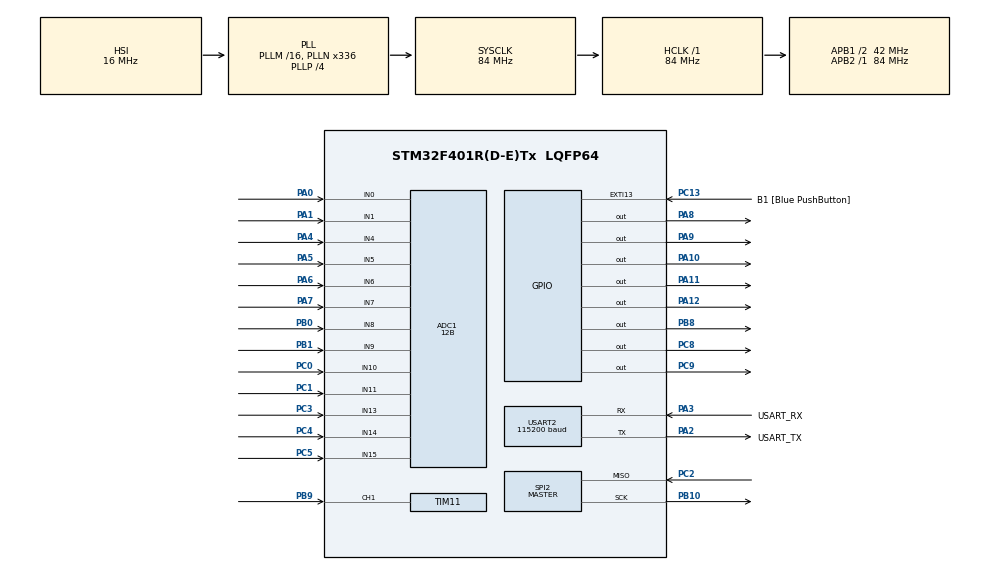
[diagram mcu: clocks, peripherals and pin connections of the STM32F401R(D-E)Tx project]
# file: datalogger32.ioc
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ADC1.Channel-0\#ChannelRegularConversion=ADC_CHANNEL_0
ADC1.ClockPrescaler=ADC_CLOCK_SYNC_PCLK_DIV4
ADC1.ContinuousConvMode=DISABLE
ADC1.DMAContinuousRequests=DISABLE
ADC1.DataAlign=ADC_DATAALIGN_RIGHT
ADC1.DiscontinuousConvMode=DISABLE
ADC1.EOCSelection=ADC_EOC_SINGLE_CONV
ADC1.EnableAnalogWatchDog=false
ADC1.ExternalTrigConv=ADC_SOFTWARE_START
ADC1.ExternalTrigConvEdge=ADC_EXTERNALTRIGCONVEDGE_NONE
ADC1.InjNumberOfConversion=0
ADC1.NbrOfConversion=1
ADC1.NbrOfConversionFlag=1
ADC1.Rank-0\#ChannelRegularConversion=1
ADC1.Resolution=ADC_RESOLUTION_12B
ADC1.SamplingTime-0\#ChannelRegularConversion=ADC_SAMPLETIME_3CYCLES
ADC1.ScanConvMode=DISABLE
ADC1.master=1
Dma.Request0=USART2_RX
Dma.USART2_RX.0.Direction=DMA_PERIPH_TO_MEMORY
Dma.USART2_RX.0.FIFOMode=DMA_FIFOMODE_DISABLE
Dma.USART2_RX.0.Instance=DMA1_Stream5
Dma.USART2_RX.0.MemDataAlignment=DMA_MDATAALIGN_BYTE
Dma.USART2_RX.0.MemInc=DMA_MINC_ENABLE
Dma.USART2_RX.0.Mode=DMA_CIRCULAR
Dma.USART2_RX.0.PeriphDataAlignment=DMA_PDATAALIGN_BYTE
Dma.USART2_RX.0.PeriphInc=DMA_PINC_DISABLE
Dma.USART2_RX.0.Priority=DMA_PRIORITY_LOW
Mcu.Family=STM32F4
Mcu.Name=STM32F401R(D-E)Tx
Mcu.Package=LQFP64
NVIC.DMA1_Stream5_IRQn=true\:0\:0\:false\:false\:true\:false
NVIC.PriorityGroup=NVIC_PRIORITYGROUP_0
NVIC.TIM1_TRG_COM_TIM11_IRQn=true\:0\:0\:false\:false\:true\:true
PA0-WKUP.Signal=ADCx_IN0
PA1.Signal=ADCx_IN1
PA10.GPIO_PuPd=GPIO_PULLDOWN
PA10.Signal=GPIO_Output
PA11.GPIO_PuPd=GPIO_PULLDOWN
PA11.Signal=GPIO_Output
PA12.GPIO_ModeDefaultOutputPP=GPIO_MODE_OUTPUT_PP
PA12.GPIO_PuPd=GPIO_PULLDOWN
PA12.Signal=GPIO_Output
PA13.GPIO_Label=TMS
PA13.Mode=Serial_Wire
PA13.Signal=SYS_JTMS-SWDIO
PA14.GPIO_Label=TCK
PA14.Mode=Serial_Wire
PA14.Signal=SYS_JTCK-SWCLK
PA2.GPIO_Label=USART_TX
PA2.GPIO_Mode=GPIO_MODE_AF_PP
PA2.GPIO_PuPd=GPIO_PULLUP
PA2.GPIO_Speed=GPIO_SPEED_FREQ_HIGH
PA2.Mode=Asynchronous
PA2.Signal=USART2_TX
PA3.GPIO_Label=USART_RX
PA3.GPIO_Mode=GPIO_MODE_AF_PP
PA3.GPIO_PuPd=GPIO_PULLUP
PA3.GPIO_Speed=GPIO_SPEED_FREQ_HIGH
PA3.Mode=Asynchronous
PA3.Signal=USART2_RX
PA4.Signal=ADCx_IN4
PA5.Signal=SharedAnalog_PA5
PA6.Signal=ADCx_IN6
PA7.Signal=ADCx_IN7
PA8.GPIO_PuPd=GPIO_PULLDOWN
PA8.Signal=GPIO_Output
PA9.GPIO_PuPd=GPIO_PULLDOWN
PA9.Signal=GPIO_Output
PB0.Signal=ADCx_IN8
PB1.Signal=ADCx_IN9
PB10.GPIO_PuPd=GPIO_PULLDOWN
PB10.Mode=RX_Only_Simplex_Unidirect_Master
PB10.Signal=SPI2_SCK
PB3.GPIO_Label=SWO
PB3.Signal=SYS_JTDO-SWO
PB8.GPIO_PuPd=GPIO_PULLDOWN
PB8.Signal=GPIO_Output
PB9.Signal=S_TIM11_CH1
PC0.Signal=ADCx_IN10
PC1.Signal=ADCx_IN11
PC13-ANTI_TAMP.GPIO_Label=B1 [Blue PushButton]
PC13-ANTI_TAMP.GPIO_ModeDefaultEXTI=GPIO_MODE_IT_FALLING
PC13-ANTI_TAMP.GPIO_PuPd=GPIO_NOPULL
PC13-ANTI_TAMP.Signal=GPXTI13
PC14-OSC32_IN.Mode=LSE-External-Oscillator
PC14-OSC32_IN.Signal=RCC_OSC32_IN
PC15-OSC32_OUT.Mode=LSE-External-Oscillator
PC15-OSC32_OUT.Signal=RCC_OSC32_OUT
PC2.GPIO_PuPd=GPIO_PULLDOWN
PC2.Mode=RX_Only_Simplex_Unidirect_Master
PC2.Signal=SPI2_MISO
PC3.Signal=ADCx_IN13
PC4.Signal=ADCx_IN14
PC5.Signal=ADCx_IN15
PC8.GPIO_PuPd=GPIO_PULLDOWN
PC8.Signal=GPIO_Output
PC9.GPIO_PuPd=GPIO_PULLDOWN
PC9.Signal=GPIO_Output
PH0\ -\ OSC_IN.Mode=HSE-External-Clock-Source
PH0\ -\ OSC_IN.Signal=RCC_OSC_IN
PH1\ -\ OSC_OUT.Mode=HSE-External-Clock-Source
PH1\ -\ OSC_OUT.Signal=RCC_OSC_OUT
ProjectManager.HeapSize=0x200
ProjectManager.StackSize=0x400
ProjectManager.TargetToolchain=Makefile
RCC.48MHZClocksFreq_Value=48000000
RCC.AHBFreq_Value=84000000
RCC.APB1CLKDivider=RCC_HCLK_DIV2
RCC.APB1Freq_Value=42000000
RCC.APB1TimFreq_Value=84000000
RCC.APB2Freq_Value=84000000
RCC.APB2TimFreq_Value=84000000
RCC.CortexFreq_Value=84000000
RCC.HCLKFreq_Value=84000000
RCC.HSE_VALUE=8000000
RCC.HSI_VALUE=16000000
RCC.PLLN=336
RCC.PLLP=RCC_PLLP_DIV4
RCC.PLLQ=7
RCC.RCC_RTC_Clock_Source=RCC_RTCCLKSOURCE_LSI
RCC.RCC_RTC_Clock_SourceVirtual=RCC_RTCCLKSOURCE_LSI
RCC.SYSCLKFreq_VALUE=84000000
RCC.SYSCLKSource=RCC_SYSCLKSOURCE_PLLCLK
RCC.VCOOutputFreq_Value=336000000
SH.ADCx_IN0.0=ADC1_IN0,IN0
SH.ADCx_IN1.0=ADC1_IN1,IN1
SH.ADCx_IN10.0=ADC1_IN10,IN10
SH.ADCx_IN11.0=ADC1_IN11,IN11
SH.ADCx_IN13.0=ADC1_IN13,IN13
SH.ADCx_IN14.0=ADC1_IN14,IN14
SH.ADCx_IN15.0=ADC1_IN15,IN15
SH.ADCx_IN4.0=ADC1_IN4,IN4
SH.ADCx_IN6.0=ADC1_IN6,IN6
SH.ADCx_IN7.0=ADC1_IN7,IN7
SH.ADCx_IN8.0=ADC1_IN8,IN8
SH.ADCx_IN9.0=ADC1_IN9,IN9
SH.S_TIM11_CH1.0=TIM11_CH1,Input_Capture1_from_TI1
SH.SharedAnalog_PA5.0=GPIO_Analog
SH.SharedAnalog_PA5.1=ADC1_IN5,IN5
SPI2.BaudRatePrescaler=SPI_BAUDRATEPRESCALER_2
SPI2.CLKPhase=SPI_PHASE_1EDGE
SPI2.DataSize=SPI_DATASIZE_8BIT
SPI2.Direction=SPI_DIRECTION_2LINES_RXONLY
SPI2.Mode=SPI_MODE_MASTER
SPI2.VirtualType=VM_MASTER
TIM11.Channel=TIM_CHANNEL_1
USART2.BaudRate=115200
USART2.VirtualMode=VM_ASYNC
VP_TIM11_VS_ClockSourceINT.Mode=Enable_Timer
board=NUCLEO-F401RE

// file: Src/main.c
/**
  ******************************************************************************
  * @file           : main.c
  * @brief          : Main program body
  ******************************************************************************
  ** This notice applies to any and all portions of this file
  * that are not between comment pairs USER CODE BEGIN and
  * USER CODE END. Other portions of this file, whether
  * inserted by the user or by software development tools
  * are owned by their respective copyright owners.
  *
  * COPYRIGHT(c) 2018 STMicroelectronics
  *
  * Redistribution and use in source and binary forms, with or without modification,
  * are permitted provided that the following conditions are met:
  *   1. Redistributions of source code must retain the above copyright notice,
  *      this list of conditions and the following disclaimer.
  *   2. Redistributions in binary form must reproduce the above copyright notice,
  *      this list of conditions and the following disclaimer in the documentation
  *      and/or other materials provided with the distribution.
  *   3. Neither the name of STMicroelectronics nor the names of its contributors
  *      may be used to endorse or promote products derived from this software
  *      without specific prior written permission.
  *
  * THIS SOFTWARE IS PROVIDED BY THE COPYRIGHT HOLDERS AND CONTRIBUTORS "AS IS"
  * AND ANY EXPRESS OR IMPLIED WARRANTIES, INCLUDING, BUT NOT LIMITED TO, THE
  * IMPLIED WARRANTIES OF MERCHANTABILITY AND FITNESS FOR A PARTICULAR PURPOSE ARE
  * DISCLAIMED. IN NO EVENT SHALL THE COPYRIGHT HOLDER OR CONTRIBUTORS BE LIABLE
  * FOR ANY DIRECT, INDIRECT, INCIDENTAL, SPECIAL, EXEMPLARY, OR CONSEQUENTIAL
  * DAMAGES (INCLUDING, BUT NOT LIMITED TO, PROCUREMENT OF SUBSTITUTE GOODS OR
  * SERVICES; LOSS OF USE, DATA, OR PROFITS; OR BUSINESS INTERRUPTION) HOWEVER
  * CAUSED AND ON ANY THEORY OF LIABILITY, WHETHER IN CONTRACT, STRICT LIABILITY,
  * OR TORT (INCLUDING NEGLIGENCE OR OTHERWISE) ARISING IN ANY WAY OUT OF THE USE
  * OF THIS SOFTWARE, EVEN IF ADVISED OF THE POSSIBILITY OF SUCH DAMAGE.
  *
  ******************************************************************************
  */
#include "main.h"
#include "stm32f4xx_hal.h"

/* USER CODE BEGIN Includes */
#include "edcMain.h"

/* USER CODE END Includes */

ADC_HandleTypeDef hadc1;

SPI_HandleTypeDef hspi2;

TIM_HandleTypeDef htim11;

UART_HandleTypeDef huart2;
DMA_HandleTypeDef hdma_usart2_rx;

/* USER CODE BEGIN PV */
/* Private variables ---------------------------------------------------------*/

/* USER CODE END PV */

void SystemClock_Config(void);
static void MX_GPIO_Init(void);
static void MX_DMA_Init(void);
static void MX_ADC1_Init(void);
static void MX_SPI2_Init(void);
static void MX_TIM11_Init(void);
static void MX_USART2_UART_Init(void);

/* USER CODE BEGIN PFP */
/* Private function prototypes -----------------------------------------------*/

/* USER CODE END PFP */

int main(void)
{

  /* MCU Configuration----------------------------------------------------------*/

  /* Reset of all peripherals, Initializes the Flash interface and the Systick. */
  HAL_Init();

  /* Configure the system clock */
  SystemClock_Config();

  /* Initialize all configured peripherals */
  MX_GPIO_Init();
  MX_DMA_Init();
  MX_ADC1_Init();
  MX_SPI2_Init();
  MX_TIM11_Init();
  MX_USART2_UART_Init();
  /* USER CODE BEGIN 2 */

  edcMain();
  /* USER CODE END 2 */

  /* Infinite loop */
  while (1)
  {

  }

}

void SystemClock_Config(void)
{

  RCC_OscInitTypeDef RCC_OscInitStruct;
  RCC_ClkInitTypeDef RCC_ClkInitStruct;
  RCC_PeriphCLKInitTypeDef PeriphClkInitStruct;

    /**Configure the main internal regulator output voltage
    */
  __HAL_RCC_PWR_CLK_ENABLE();

  __HAL_PWR_VOLTAGESCALING_CONFIG(PWR_REGULATOR_VOLTAGE_SCALE2);

    /**Initializes the CPU, AHB and APB busses clocks
    */
  RCC_OscInitStruct.OscillatorType = RCC_OSCILLATORTYPE_HSI|RCC_OSCILLATORTYPE_HSE;
  RCC_OscInitStruct.HSEState = RCC_HSE_BYPASS;
  RCC_OscInitStruct.HSIState = RCC_HSI_ON;
  RCC_OscInitStruct.HSICalibrationValue = 16;
  RCC_OscInitStruct.PLL.PLLState = RCC_PLL_ON;
  RCC_OscInitStruct.PLL.PLLSource = RCC_PLLSOURCE_HSI;
  RCC_OscInitStruct.PLL.PLLM = 16;
  RCC_OscInitStruct.PLL.PLLN = 336;
  RCC_OscInitStruct.PLL.PLLP = RCC_PLLP_DIV4;
  RCC_OscInitStruct.PLL.PLLQ = 7;
  if (HAL_RCC_OscConfig(&RCC_OscInitStruct) != HAL_OK)
  {
    _Error_Handler(__FILE__, __LINE__);
  }

    /**Initializes the CPU, AHB and APB busses clocks
    */
  RCC_ClkInitStruct.ClockType = RCC_CLOCKTYPE_HCLK|RCC_CLOCKTYPE_SYSCLK
                              |RCC_CLOCKTYPE_PCLK1|RCC_CLOCKTYPE_PCLK2;
  RCC_ClkInitStruct.SYSCLKSource = RCC_SYSCLKSOURCE_PLLCLK;
  RCC_ClkInitStruct.AHBCLKDivider = RCC_SYSCLK_DIV1;
  RCC_ClkInitStruct.APB1CLKDivider = RCC_HCLK_DIV2;
  RCC_ClkInitStruct.APB2CLKDivider = RCC_HCLK_DIV1;

  if (HAL_RCC_ClockConfig(&RCC_ClkInitStruct, FLASH_LATENCY_2) != HAL_OK)
  {
    _Error_Handler(__FILE__, __LINE__);
  }

  PeriphClkInitStruct.PeriphClockSelection = RCC_PERIPHCLK_RTC;
  PeriphClkInitStruct.RTCClockSelection = RCC_RTCCLKSOURCE_LSI;
  if (HAL_RCCEx_PeriphCLKConfig(&PeriphClkInitStruct) != HAL_OK)
  {
    _Error_Handler(__FILE__, __LINE__);
  }

    /**Configure the Systick interrupt time
    */
  HAL_SYSTICK_Config(HAL_RCC_GetHCLKFreq()/1000);

    /**Configure the Systick
    */
  HAL_SYSTICK_CLKSourceConfig(SYSTICK_CLKSOURCE_HCLK);

  /* SysTick_IRQn interrupt configuration */
  HAL_NVIC_SetPriority(SysTick_IRQn, 0, 0);
}

/* ADC1 init function */
static void MX_ADC1_Init(void)
{

  ADC_ChannelConfTypeDef sConfig;

    /**Configure the global features of the ADC (Clock, Resolution, Data Alignment and number of conversion)
    */
  hadc1.Instance = ADC1;
  hadc1.Init.ClockPrescaler = ADC_CLOCK_SYNC_PCLK_DIV4;
  hadc1.Init.Resolution = ADC_RESOLUTION_12B;
  hadc1.Init.ScanConvMode = DISABLE;
  hadc1.Init.ContinuousConvMode = DISABLE;
  hadc1.Init.DiscontinuousConvMode = DISABLE;
  hadc1.Init.ExternalTrigConvEdge = ADC_EXTERNALTRIGCONVEDGE_NONE;
  hadc1.Init.ExternalTrigConv = ADC_SOFTWARE_START;
  hadc1.Init.DataAlign = ADC_DATAALIGN_RIGHT;
  hadc1.Init.NbrOfConversion = 1;
  hadc1.Init.DMAContinuousRequests = DISABLE;
  hadc1.Init.EOCSelection = ADC_EOC_SINGLE_CONV;
  if (HAL_ADC_Init(&hadc1) != HAL_OK)
  {
    _Error_Handler(__FILE__, __LINE__);
  }

    /**Configure for the selected ADC regular channel its corresponding rank in the sequencer and its sample time.
    */
  sConfig.Channel = ADC_CHANNEL_0;
  sConfig.Rank = 1;
  sConfig.SamplingTime = ADC_SAMPLETIME_3CYCLES;
  if (HAL_ADC_ConfigChannel(&hadc1, &sConfig) != HAL_OK)
  {
    _Error_Handler(__FILE__, __LINE__);
  }

}

/* SPI2 init function */
static void MX_SPI2_Init(void)
{

  /* SPI2 parameter configuration*/
  hspi2.Instance = SPI2;
  hspi2.Init.Mode = SPI_MODE_MASTER;
  hspi2.Init.Direction = SPI_DIRECTION_2LINES_RXONLY;
  hspi2.Init.DataSize = SPI_DATASIZE_8BIT;
  hspi2.Init.CLKPolarity = SPI_POLARITY_LOW;
  hspi2.Init.CLKPhase = SPI_PHASE_1EDGE;
  hspi2.Init.NSS = SPI_NSS_SOFT;
  hspi2.Init.BaudRatePrescaler = SPI_BAUDRATEPRESCALER_256;
  hspi2.Init.FirstBit = SPI_FIRSTBIT_MSB;
  hspi2.Init.TIMode = SPI_TIMODE_DISABLE;
  hspi2.Init.CRCCalculation = SPI_CRCCALCULATION_DISABLE;
  hspi2.Init.CRCPolynomial = 10;
  if (HAL_SPI_Init(&hspi2) != HAL_OK)
  {
    _Error_Handler(__FILE__, __LINE__);
  }

}

/* TIM11 init function */
static void MX_TIM11_Init(void)
{

  TIM_IC_InitTypeDef sConfigIC;

  htim11.Instance = TIM11;
  htim11.Init.Prescaler = 0;
  htim11.Init.CounterMode = TIM_COUNTERMODE_UP;
  htim11.Init.Period = 0;
  htim11.Init.ClockDivision = TIM_CLOCKDIVISION_DIV1;
  if (HAL_TIM_Base_Init(&htim11) != HAL_OK)
  {
    _Error_Handler(__FILE__, __LINE__);
  }

  if (HAL_TIM_IC_Init(&htim11) != HAL_OK)
  {
    _Error_Handler(__FILE__, __LINE__);
  }

  sConfigIC.ICPolarity = TIM_INPUTCHANNELPOLARITY_RISING;
  sConfigIC.ICSelection = TIM_ICSELECTION_DIRECTTI;
  sConfigIC.ICPrescaler = TIM_ICPSC_DIV1;
  sConfigIC.ICFilter = 0;
  if (HAL_TIM_IC_ConfigChannel(&htim11, &sConfigIC, TIM_CHANNEL_1) != HAL_OK)
  {
    _Error_Handler(__FILE__, __LINE__);
  }

}

/* USART2 init function */
static void MX_USART2_UART_Init(void)
{

  huart2.Instance = USART2;
  huart2.Init.BaudRate = 115200;
  huart2.Init.WordLength = UART_WORDLENGTH_8B;
  huart2.Init.StopBits = UART_STOPBITS_1;
  huart2.Init.Parity = UART_PARITY_NONE;
  huart2.Init.Mode = UART_MODE_TX_RX;
  huart2.Init.HwFlowCtl = UART_HWCONTROL_NONE;
  huart2.Init.OverSampling = UART_OVERSAMPLING_16;
  if (HAL_UART_Init(&huart2) != HAL_OK)
  {
    _Error_Handler(__FILE__, __LINE__);
  }

}

static void MX_DMA_Init(void)
{
  /* DMA controller clock enable */
  __HAL_RCC_DMA1_CLK_ENABLE();

  /* DMA interrupt init */
  /* DMA1_Stream5_IRQn interrupt configuration */
  HAL_NVIC_SetPriority(DMA1_Stream5_IRQn, 0, 0);
  HAL_NVIC_EnableIRQ(DMA1_Stream5_IRQn);

}

/** Configure pins as
        * Analog
        * Input
        * Output
        * EVENT_OUT
        * EXTI
     PA5   ------> SharedAnalog_PA5
*/
static void MX_GPIO_Init(void)
{

  GPIO_InitTypeDef GPIO_InitStruct;

  /* GPIO Ports Clock Enable */
  __HAL_RCC_GPIOC_CLK_ENABLE();
  __HAL_RCC_GPIOH_CLK_ENABLE();
  __HAL_RCC_GPIOA_CLK_ENABLE();
  __HAL_RCC_GPIOB_CLK_ENABLE();

  /*Configure GPIO pin Output Level */
  HAL_GPIO_WritePin(GPIOC, GPIO_PIN_8|GPIO_PIN_9, GPIO_PIN_RESET);

  /*Configure GPIO pin Output Level */
  HAL_GPIO_WritePin(GPIOA, GPIO_PIN_8|GPIO_PIN_9|GPIO_PIN_10|GPIO_PIN_11
                          |GPIO_PIN_12, GPIO_PIN_RESET);

  /*Configure GPIO pin Output Level */
  HAL_GPIO_WritePin(GPIOB, GPIO_PIN_8, GPIO_PIN_RESET);

  /*Configure GPIO pin : B1_Pin */
  GPIO_InitStruct.Pin = B1_Pin;
  GPIO_InitStruct.Mode = GPIO_MODE_IT_FALLING;
  GPIO_InitStruct.Pull = GPIO_NOPULL;
  HAL_GPIO_Init(B1_GPIO_Port, &GPIO_InitStruct);

  /*Configure GPIO pin : PA5 */
  GPIO_InitStruct.Pin = GPIO_PIN_5;
  GPIO_InitStruct.Mode = GPIO_MODE_ANALOG;
  GPIO_InitStruct.Pull = GPIO_NOPULL;
  HAL_GPIO_Init(GPIOA, &GPIO_InitStruct);

  /*Configure GPIO pins : PC8 PC9 */
  GPIO_InitStruct.Pin = GPIO_PIN_8|GPIO_PIN_9;
  GPIO_InitStruct.Mode = GPIO_MODE_OUTPUT_PP;
  GPIO_InitStruct.Pull = GPIO_PULLDOWN;
  GPIO_InitStruct.Speed = GPIO_SPEED_FREQ_LOW;
  HAL_GPIO_Init(GPIOC, &GPIO_InitStruct);

  /*Configure GPIO pins : PA8 PA9 PA10 PA11
                           PA12 */
  GPIO_InitStruct.Pin = GPIO_PIN_8|GPIO_PIN_9|GPIO_PIN_10|GPIO_PIN_11
                          |GPIO_PIN_12;
  GPIO_InitStruct.Mode = GPIO_MODE_OUTPUT_PP;
  GPIO_InitStruct.Pull = GPIO_PULLDOWN;
  GPIO_InitStruct.Speed = GPIO_SPEED_FREQ_LOW;
  HAL_GPIO_Init(GPIOA, &GPIO_InitStruct);

  /*Configure GPIO pin : PB8 */
  GPIO_InitStruct.Pin = GPIO_PIN_8;
  GPIO_InitStruct.Mode = GPIO_MODE_OUTPUT_PP;
  GPIO_InitStruct.Pull = GPIO_PULLDOWN;
  GPIO_InitStruct.Speed = GPIO_SPEED_FREQ_LOW;
  HAL_GPIO_Init(GPIOB, &GPIO_InitStruct);

}

void _Error_Handler(char *file, int line)
{
  while(1)
  {
  }
}

/************************ (C) COPYRIGHT STMicroelectronics *****END OF FILE****/
